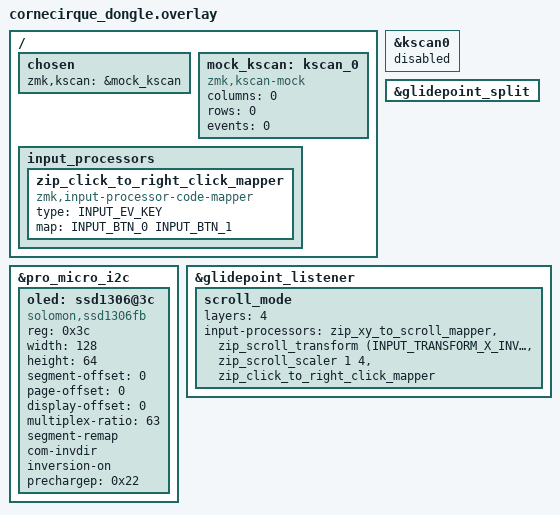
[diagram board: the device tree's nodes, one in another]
#include "cornecirque.dtsi"
#include <input/processors.dtsi>
#include <dt-bindings/zmk/input_transform.h>
#include <zephyr/dt-bindings/input/input-event-codes.h>

/ {
    chosen {
        zmk,kscan = &mock_kscan;
    };

    mock_kscan: kscan_0 {
        compatible = "zmk,kscan-mock";
        columns = <0>;
        rows = <0>;
        events = <0>;
    };

    input_processors {
        zip_click_to_right_click_mapper: zip_click_to_right_click_mapper {
            compatible = "zmk,input-processor-code-mapper";
            #input-processor-cells = <0>;
            type = <INPUT_EV_KEY>;
            map = <INPUT_BTN_0 INPUT_BTN_1>;
        };
    };
};

&kscan0 {
    status = "disabled";
};

&pro_micro_i2c {
    status = "okay";

    oled: ssd1306@3c {
        compatible = "solomon,ssd1306fb";
        reg = <0x3c>;
        width = <128>;
        height = <64>;
        segment-offset = <0>;
        page-offset = <0>;
        display-offset = <0>;
        multiplex-ratio = <63>;
        segment-remap;
        com-invdir;
        inversion-on;
        prechargep = <0x22>;
    };
};

&glidepoint_split {
    status = "okay";
};

&glidepoint_listener {
    status = "okay";

    scroll_mode {
        layers = <4>;
        input-processors = <&zip_xy_to_scroll_mapper>, <&zip_scroll_transform (INPUT_TRANSFORM_X_INVERT)>, <&zip_scroll_scaler 1 4>, <&zip_click_to_right_click_mapper>;
    };
};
